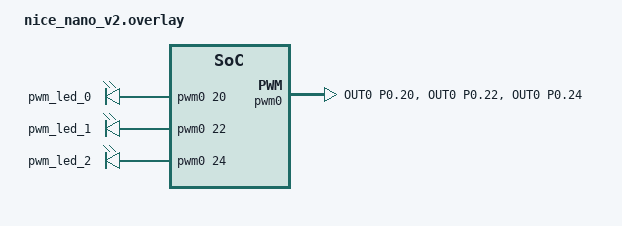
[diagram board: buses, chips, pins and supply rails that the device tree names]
#include <dt-bindings/led/led.h>

&pwm0 {
  status = "okay";
  pinctrl-0 = <&pwm0_default>;
  pinctrl-1 = <&pwm0_sleep>;
  pinctrl-names = "default", "sleep";
};

&pinctrl {
    pwm0_default: pwm0_default {
        group1 {
            // Use P1.04 for LED backlight
            psels = <NRF_PSEL(PWM_OUT0, 0, 20)>;
	      };
        group2 {
            // Use P1.04 for LED backlight
            psels = <NRF_PSEL(PWM_OUT0, 0, 22)>;
	      };
        group3 {
            // Use P1.04 for LED backlight
            psels = <NRF_PSEL(PWM_OUT0, 0, 24)>;
	      };
    };

    pwm0_sleep: pwm0_sleep {
        group1 {
            // Use P1.04 for LED backlight
            psels = <NRF_PSEL(PWM_OUT0, 0, 20)>;
            low-power-enable;
	      };
        group2 {
            // Use P1.04 for LED backlight
            psels = <NRF_PSEL(PWM_OUT0, 0, 22)>;
            low-power-enable;
	      };
        group3 {
            // Use P1.04 for LED backlight
            psels = <NRF_PSEL(PWM_OUT0, 0, 24)>;
            low-power-enable;
	      };
    };
};

// &pwm0 {
//     status = "okay";
//     ch0-pin = <20>; /* LED 0 */
//     ch1-pin = <22>; /* LED 1 */
//     ch2-pin = <24>; /* LED 2 */
// };

/ {
    backlight: pwmleds {
        compatible = "pwm-leds";
        label = "Backlight LEDs";
        pwm_led_0 {
            pwms = <&pwm0 20 10000 PWM_POLARITY_NORMAL>; /* LED 0 */
        };
        pwm_led_1 {
            pwms = <&pwm0 22 10000 PWM_POLARITY_NORMAL>; /* LED 1 */
        };
        pwm_led_2 {
            pwms = <&pwm0 24 10000 PWM_POLARITY_NORMAL>; /* LED 2 */
        };
    };
};


/ {
	chosen {
		 zmk,backlight = &backlight;
	};
};
